# K1921VG1T register map
Vendor: NIIET; Series: K1921VGx; File version: 2.8
CPU: other r0p1, little endian, MPU, FPU, 4 interrupt priority bits
Registers are 32-bit, read-write, reset 0x0 unless marked. A register's access mark holds for its fields unless they carry their own. Offsets are from the block's base; [hi:lo] are bit positions.

## USBHC0 — USBHC control registers
Base 0x41081000
Same registers: USBHC1 0x41091000
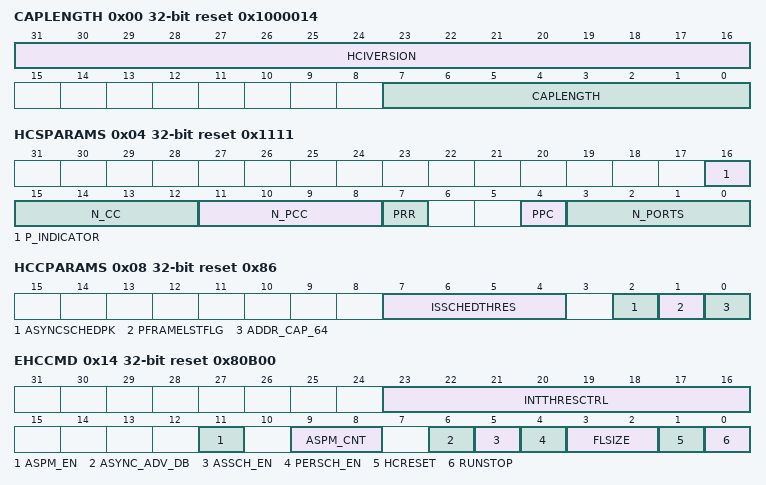
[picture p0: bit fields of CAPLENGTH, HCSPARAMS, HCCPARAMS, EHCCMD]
0x00 CAPLENGTH ro reset 0x1000014 — USBHC Capabilities register
  [31:16] HCIVERSION — Host Controller Interface Version Number
  [7:0] CAPLENGTH — Capabilities register length
0x04 HCSPARAMS ro reset 0x1111 — USBHC Structural Parameters register
  [16] P_INDICATOR — Port Indicator
  [15:12] N_CC — Number of Companion Controller
  [11:8] N_PCC — Number of Ports per Companion Controller
  [7] PRR — Port Routing Rules
  [4] PPC — Port Power Control
  [3:0] N_PORTS — Number of physical downstream ports implemented
0x08 HCCPARAMS ro reset 0x86 — USBHC Capability Parameters register
  [7:4] ISSCHEDTHRES — Isochronous Scheduling Threshold
  [2] ASYNCSCHEDPK — Asynchronous Schedule Park Capability
  [1] PFRAMELSTFLG — Programmable Frame List Flag
  [0] ADDR_CAP_64 — 64-bit Addressing Capability
0x14 EHCCMD reset 0x80B00 — USBHC EHC Command register
  [23:16] INTTHRESCTRL — Interrupt Threshold Control
  [11] ASPM_EN — Asynchronous Schedule Park Mode Enable
  [9:8] ASPM_CNT — Asynchronouos Schedule Park Mode Count
  [6] ASYNC_ADV_DB — Interrupt on Async Advance Doorbell
  [5] ASSCH_EN — Asynchronous Schedule Enable
  [4] PERSCH_EN — Periodic Schedule Enable
  [3:2] FLSIZE — Frame List Size
  [1] HCRESET — Host Controller Reset
  [0] RUNSTOP
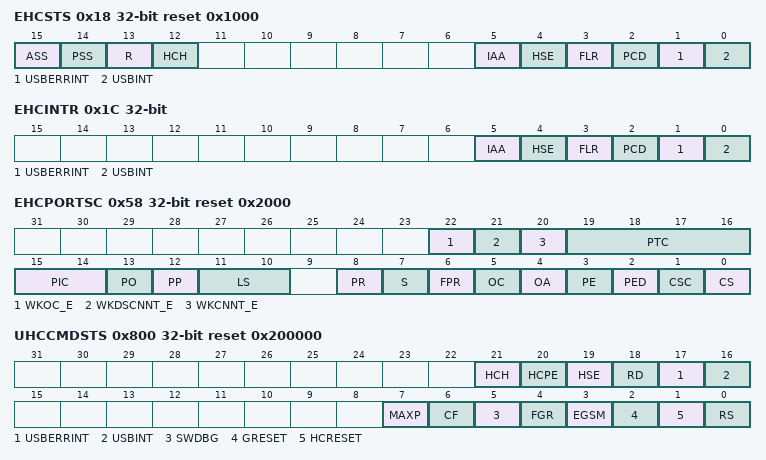
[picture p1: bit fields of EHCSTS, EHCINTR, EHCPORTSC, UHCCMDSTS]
0x18 EHCSTS reset 0x1000 — USBHC EHC Status register
  [15] ASS ro — Asynchronous Schedule Status
  [14] PSS ro — Periodic Schedule Status
  [13] R ro — Reclamation
  [12] HCH ro — HCHalted
  [5] IAA — Interrupt on Async Advance
  [4] HSE — Host System Error
  [3] FLR — Frame List Rollover
  [2] PCD — Port Change Detect
  [1] USBERRINT — USB Error Interrupt
  [0] USBINT — USB Interrupt
0x1C EHCINTR — USBHC EHC Interrupt Enable register
  [5] IAA — Interrupt on Async Advance Enable
  [4] HSE — Host System Error Enable
  [3] FLR — Frame List Rollover Enable
  [2] PCD — Port Change Detect Enable
  [1] USBERRINT — USB Error Interrupt Enable
  [0] USBINT — USB Interrupt Enable
0x20 FRINDEX — USBHC EHC Frame Index register
  [13:0] FRAME_IDX — Frame Index
0x24 CTRLDSSEG — USBHC EHC Control Data Structure Segment register
0x28 PERIODICLISTBASE — USBHC EHC Periodic Frame List Base Address Register
  [31:12] BASEADDRESS
0x2C ASYNCLISTADDR — USBHC EHC Current Asynchronous List Address register
  [31:5] LPL
0x54 CONFIGFLAG — USBHC EHC Configure Flag Register Bit Definitions register
  [0] CF — Configure Flag
0x58 EHCPORTSC reset 0x2000 — USBHC EHC Port Status and Control register
  [22] WKOC_E — Wake on Over-current Enable
  [21] WKDSCNNT_E — Wake on Disconnect Enable
  [20] WKCNNT_E — Wake on Connect Enable
  [19:16] PTC — Port Test Control
  [15:14] PIC — Port Test Control
  [13] PO — Port Owner
  [12] PP — Port Power
  [11:10] LS ro — Line Status
    0=SE0 (Not LS devoce, perform EHCI reset); 1=JSTATE (Not LS device, perform EHCI reset); 2=KSTATE (LS device, release ownership of port); 3=UNDEFINED (Not LS device, perform EHCI reset)
  [8] PR — Port Reset
  [7] S — Suspend
  [6] FPR — Force Port Resume
  [5] OC — Over-current Change
  [4] OA ro — Over-current Active
  [3] PE — Port Enable/Disable Change
  [2] PED — Port Enabled/Disabled
  [1] CSC — Connect Status Change
  [0] CS ro — Current Connect Status
0x800 UHCCMDSTS reset 0x200000 — USBHC UHC Command and Status register
  [21] HCH ro — HCHalted
  [20] HCPE — Host Controller Process Error
  [19] HSE — Host System Error
  [18] RD — Resume Detect
  [17] USBERRINT — USB Error Interrupt
  [16] USBINT — USB Interrupt
  [7] MAXP — Maximum Packet Size
  [6] CF — Confiduire Flag
  [5] SWDBG — Software Debug
  [4] FGR — Force Global Resume
  [3] EGSM — Enter Global Suspend Mode
  [2] GRESET — Global Reset
  [1] HCRESET — Host Controller Reset
  [0] RS — Run/Stop
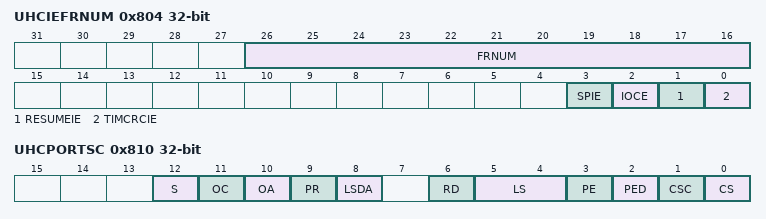
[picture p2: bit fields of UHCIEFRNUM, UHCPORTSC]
0x804 UHCIEFRNUM — USBHC UHC Interrupt Enable and Frame Number register
  [26:16] FRNUM — Frame List Current Index/Frame Number
  [3] SPIE — Short Packet Interrupt Enable
  [2] IOCE — Interrupt on Complete Enable
  [1] RESUMEIE — Resume Interrupt Enable
  [0] TIMCRCIE — Timeout/CRC Interrupt Enable
0x808 FRBASEADD — USBHC UHC Frame List Base Address register
  [31:12] BASEADDRESS — Beginning address of the Frame List in the system memory
0x80C SOFMOD reset 0x40 — USBHC UHC Start of Frame Modify register
  [6:0] SOFVAL — SOF Timing Value
0x810 UHCPORTSC — USBHC UHC Port Status and Control register
  [12] S — Suspend
  [11] OC — Over-current Change
  [10] OA ro — Over-current Active
  [9] PR — Port Reset
  [8] LSDA ro — Low Speed Device Attached
  [6] RD — Resume Detect
  [5:4] LS ro — Line Status
  [3] PE — Port Enable/Disable Change
  [2] PED — Port Enabled/Disabled
  [1] CSC — Connect Status Change
  [0] CS ro — Current Connect Status
